# M471 register map
File version: 1.0
M471 SVD file
Registers are 32-bit, read-write, reset 0x0 unless marked. A register's access mark holds for its fields unless they carry their own. Offsets are from the block's base; lines under a group give offsets from that group; [hi:lo] are bit positions; {n}, {i} and the like mark numbered series; 'fields as' and 'values as' point back to an identical list; <NAME> marks a mode.

## Memory map
0x40000000 SYS blocks up to offset 0x404 — SYS Register Map
0x40000200 CLK blocks up to offset 0x94 — CLK Register Map
0x40000300 NMI size 0x8 — NMI Register Map
0x40004000 GPIO blocks up to offset 0xA20 — GPIO Register Map
0x40008000 PDMA blocks up to offset 0x488 — PDMA Register Map
0x4000C000 FMC blocks up to offset 0xE4 — FMC Register Map
0x4000F000 DFMC blocks up to offset 0x50 — DFMC Register Map
0x40031000 CRC size 0x10 — CRC Register Map
0x40040000 WDT size 0xC — WDT Register Map
0x40040100 WWDT size 0x10 — WWDT Register Map
0x40041000 RTC blocks up to offset 0x114 — RTC Register Map
0x40043000 EADC blocks up to offset 0xFFC — EADC Register Map
0x40045000 ACMP01 size 0x18 — ACMP Register Map
0x40047000 DAC blocks up to offset 0x24 — DAC Register Map
0x40050000 TMR01 blocks up to offset 0x178 — TIMER Register Map
0x40051000 TMR23 blocks up to offset 0x178 — TIMER Register Map
0x40058000 EPWM0 blocks up to offset 0x380 — EPWM Register Map
0x40059000 EPWM1 blocks up to offset 0x380 — EPWM Register Map
0x4005A000 BPWM0 blocks up to offset 0x334 — BPWM Register Map
0x4005B000 BPWM1 blocks up to offset 0x334 — BPWM Register Map
0x4005F000 CIR0 blocks up to offset 0x48 — CIR0 Register Map
0x40061000 SPI0 blocks up to offset 0x6C — SPI Register Map
0x40062000 SPI1 blocks up to offset 0x6C — SPI Register Map
0x40070000 UART0 size 0x4C — UART Register Map
0x40071000 UART1 size 0x4C — UART Register Map
0x40072000 UART2 blocks up to offset 0x4C — UART Register Map
0x40073000 UART3 blocks up to offset 0x4C — UART Register Map
0x40074000 UART4 blocks up to offset 0x4C — UART Register Map
0x40075000 UART5 blocks up to offset 0x4C — UART Register Map
0x40080000 I2C0 blocks up to offset 0x6C — I2C Register Map
0x40081000 I2C1 blocks up to offset 0x6C — I2C Register Map
0x400BA000 PRNG size 0x30 — PRNG Register Map
0xE000E000 SCS blocks up to offset 0xD24 — SYST_SCR Register Map
0xE000E100 NVIC blocks up to offset 0xE04 — NVIC Register Map

## NVIC — NVIC Register Map
Base 0xE000E100
{0x0+4i} NVIC_ISER{i} (i=0..3) — IRQ0 ~ IRQ111 Set-enable Control Register
  [31:0] SETENA — Interrupt Set Enable Bit. The NVIC_ISER0-NVIC_ISER{i} registers enable interrupts, and show which interrupts are enabled. Write Operation:
    0=No effect. Interrupt Disabled; 1=Interrupt Enabled
{0x80+4i} NVIC_ICER{i} (i=0..3) — IRQ0 ~ IRQ111 Clear-enable Control Register
  [31:0] CALENA — Interrupt Clear Enable Bit. The NVIC_ICER0-NVIC_ICER{i} registers disable interrupts, and show which interrupts are enabled. Write Operation:
    0=No effect. Interrupt Disabled; 1=Interrupt Disabled. Interrupt Enabled
{0x100+4i} NVIC_ISPR{i} (i=0..3) — IRQ0 ~ IRQ111 Set-pending Control Register
  [31:0] SETPEND — Interrupt Set-pending. The NVIC_ISPR0-NVIC_ISPR{i} registers force interrupts into the pending state, and show which interrupts are pending. Write Operation:
    0=No effect. Interrupt is not pending; 1=Changes interrupt state to pending. Interrupt is pending
{0x180+4i} NVIC_ICPR{i} (i=0..3) — IRQ0 ~ IRQ111 Clear-pending Control Register
  [31:0] CALPEND — Interrupt Clear-pending. The NVIC_ICPR0-NVIC_ICPR{i} registers remove the pending state from interrupts, and show which interrupts are pending. Write Operation:
    0=No effect. Interrupt is not pending; 1=Removes pending state an interrupt. Interrupt is pending
{0x200+4i} NVIC_IABR{i} (i=0..3) — IRQ0 ~ IRQ111 Active Bit Register
  [31:0] ACTIVE — Interrupt Active Flags. The NVIC_IABR0-NVIC_IABR{i} registers indicate which interrupts are active.
    0=interrupt not active; 1=interrupt active
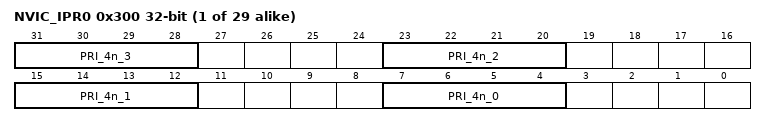
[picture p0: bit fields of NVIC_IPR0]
{0x300+4i} NVIC_IPR{i} (i=0..28) — IRQ0 ~ IRQ111 Priority Control Register
  [8n+7:8n+4] PRI_4n_{n} (n=0..3) — Priority of IRQ_4n+{n} '0' denotes the highest priority and '15' denotes the lowest priority
0xE00 STIR — Software Trigger Interrupt Registers
  [8:0] INTID — Interrupt ID. Write to the STIR To Generate An Interrupt from Software. When the USERSETMPEND bit in the SCR is set to 1, unprivileged software can access the STIR. Interrupt ID of the interrupt to trigger, in the range 0-63. For example, a value of 0x03 specifies interrupt IRQ3.
